# ATtiny48 device description
Architecture: AVR8; Family: tinyAVR
Registers are 8-bit, access not given, no defined reset value unless marked. A register's access mark holds for its fields unless they carry their own. Offsets are from the block's base; [hi:lo] are bit positions.

## PORTB — I/O Port
Instances: PORTB 0x00
0x23 PINB — Port B Input Pins
0x24 DDRB — Port B Data Direction Register
0x25 PORTB — Port B Data Register

## PORTD — I/O Port
Instances: PORTD 0x00
0x29 PIND — Port D Input Pins
0x2A DDRD — Port D Data Direction Register
0x2B PORTD — Port D Data Register

## PORTC — I/O Port
Instances: PORTC 0x00
0x26 PINC — Port C Input Pins
0x27 DDRC — Port C Data Direction Register
0x28 PORTC — Port C Data Register

## PORTA — I/O Port
Instances: PORTA 0x00
0x2C PINA bits used 3:0 — Port A Input Pins
0x2D DDRA bits used 3:0 — Port A Data Direction Register
0x2E PORTA bits used 3:0 — Port A Data Register

## SPI — Serial Peripheral Interface
Instances: SPI 0x00
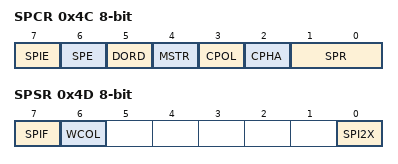
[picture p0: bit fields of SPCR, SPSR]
0x4C SPCR — SPI Control Register
  [7] SPIE — SPI Interrupt Enable
  [6] SPE — SPI Enable
  [5] DORD — Data Order
  [4] MSTR — Master/Slave Select
  [3] CPOL — Clock polarity
  [2] CPHA — Clock Phase
  [1:0] SPR — SPI Clock Rate Selects
    0=fosc/4; 1=fosc/16; 2=fosc/64; 3=fosc/128; 4=fosc/2; 5=fosc/8; 6=fosc/32; 7=fosc/64
0x4D SPSR — SPI Status Register
  [7] SPIF — SPI Interrupt Flag
  [6] WCOL — Write Collision Flag
  [0] SPI2X — Double SPI Speed Bit
0x4E SPDR — SPI Data Register

## WDT — Watchdog Timer
Instances: WDT 0x00
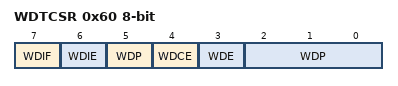
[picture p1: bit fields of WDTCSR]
0x60 WDTCSR — Watchdog Timer Control Register
  [7] WDIF — Watchdog Timeout Interrupt Flag
  [6] WDIE — Watchdog Timeout Interrupt Enable
  [4] WDCE — Watchdog Change Enable
  [3] WDE — Watch Dog Enable
  [5,2:0] WDP — Watchdog Timer Prescaler Bits
    0=Oscillator Cycles 2K; 1=Oscillator Cycles 4K; 2=Oscillator Cycles 8K; 3=Oscillator Cycles 16K; 4=Oscillator Cycles 32K; 5=Oscillator Cycles 64K; 6=Oscillator Cycles 128K; 7=Oscillator Cycles 256K; 8=Oscillator Cycles 512K; 9=Oscillator Cycles 1024K

## CPU — CPU Registers
Instances: CPU 0x00
Parameters: CORE_VERSION=V2, NEW_INSTRUCTIONS=lpm rd,z+
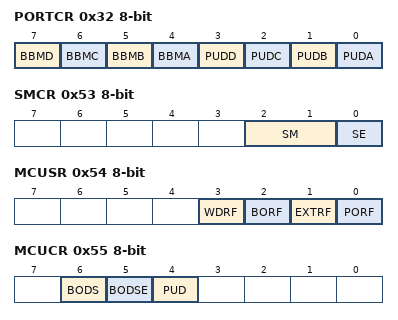
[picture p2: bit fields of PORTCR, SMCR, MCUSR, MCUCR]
0x32 PORTCR — Port Configuration Register
  [7] BBMD, [6] BBMC, [5] BBMB, [4] BBMA, [3] PUDD, [2] PUDC, [1] PUDB, [0] PUDA
0x3E GPIOR0 — General Purpose I/O Register 0
0x4A GPIOR1 — General Purpose I/O Register 1
0x4B GPIOR2 — General Purpose I/O Register 2
0x53 SMCR — Sleep Mode Control Register
  [2:1] SM — Sleep Mode
    0=IDLE; 1=ADC (ADC Noise Reduction (If Available)); 2=PDOWN (Power Down); 3=PSAVE (Power Save)
  [0] SE — Sleep Enable
0x54 MCUSR — MCU Status Register
  [3] WDRF — Watchdog Reset Flag
  [2] BORF — Brown-out Reset Flag
  [1] EXTRF — External Reset Flag
  [0] PORF — Power-on reset flag
0x55 MCUCR — MCU Control Register
  [6] BODS — BOD Sleep
  [5] BODSE — BOD Sleep Enable
  [4] PUD — Pull-up Disable
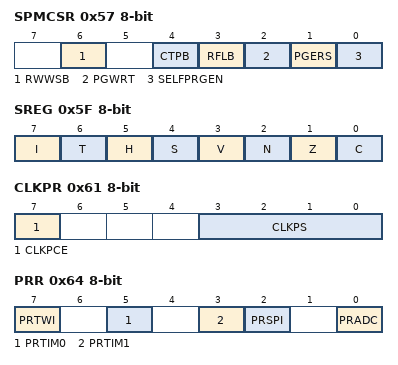
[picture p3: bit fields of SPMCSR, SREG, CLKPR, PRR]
0x57 SPMCSR — Store Program Memory Control Register
  [6] RWWSB — Read-While-Write Section Busy
  [4] CTPB — Clear Temporary Page Buffer
  [3] RFLB — Read Fuse and Lock Bits
  [2] PGWRT — Page Write
  [1] PGERS — Page Erase
  [0] SELFPRGEN — Self Programming Enable
0x5D SPL — Stack Pointer Low
0x5E SPH bits used 0 — Stack Pointer High
0x5F SREG — Status Register
  [7] I — Global Interrupt Enable
  [6] T — Bit Copy Storage
  [5] H — Half Carry Flag
  [4] S — Sign Bit
  [3] V — Two's Complement Overflow Flag
  [2] N — Negative Flag
  [1] Z — Zero Flag
  [0] C — Carry Flag
0x61 CLKPR — Clock Prescale Register
  [7] CLKPCE — Clock Prescaler Change Enable
  [3:0] CLKPS — Clock Prescaler Select Bits
    0=1; 1=2; 2=4; 3=8; 4=16; 5=32; 6=64; 7=128; 8=256
0x64 PRR — Power Reduction Register
  [7] PRTWI — Power Reduction TWI
  [5] PRTIM0 — Power Reduction Timer/Counter0
  [3] PRTIM1 — Power Reduction Timer/Counter1
  [2] PRSPI — Power Reduction Serial Peripheral Interface
  [0] PRADC — Power Reduction ADC
0x66 OSCCAL — Oscillator Calibration Value
  [7:0] OSCCAL — Oscillator Calibration
Value list OSCCAL_VALUE_ADDRESSES: 0=8_0_MHz
